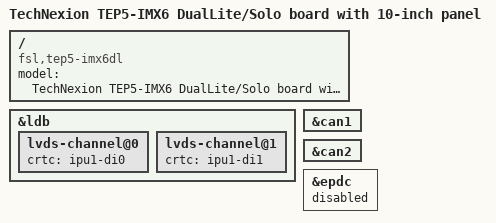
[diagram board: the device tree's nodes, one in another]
/*
 * Copyright 2018 TechNexion Ltd.
 *
 * Author: Wig Cheng <wig.cheng@technexion.com>
 *	   Richard Hu <richard.hu@technexion.com>
 *
 * This program is free software; you can redistribute it and/or modify
 * it under the terms of the GNU General Public License version 2 as
 * published by the Free Software Foundation.
 *
 */
/dts-v1/;

#include <dt-bindings/interrupt-controller/irq.h>
#include "imx6dl.dtsi"
#include "imx6qdl-tep5.dtsi"

/ {
	model = "TechNexion TEP5-IMX6 DualLite/Solo board with 10-inch panel";
	compatible = "fsl,tep5-imx6dl", "fsl,imx6dl";
};

&ldb {
	lvds-channel@0 {
		crtc = "ipu1-di0";
	};

	lvds-channel@1 {
		crtc = "ipu1-di1";
	};
};

&can1{
	status = "okay";
};

&can2{
	status = "okay";
};

#if 0
&mxcfb3 {
	status = "okay";
};

&mxcfb4 {
	status = "okay";
};
#endif

&epdc {
	status = "disabled";
};
